# F28x7x_dcsm_z1_regs register map
Vendor: Texas Instruments
Peripheral module from a debugger description file (folder C2000).
Address unit: 16 bits
Registers are 32-bit, read-only, no defined reset value unless marked. A register's access mark holds for its fields unless they carry their own. Offsets are as the file gives them; lines under a group give offsets from that group; [hi:lo] are bit positions; {n}, {i} and the like mark numbered series; 'fields as' and 'values as' point back to an identical list; <NAME> marks a mode.

## DCSM_Z1_REGS — DCSM Z1 Registers
0x00 Z1_LINKPOINTER — Zone 1 Link Pointer
  [28:0] LINKPOINTER — Zone1 LINK Pointer.
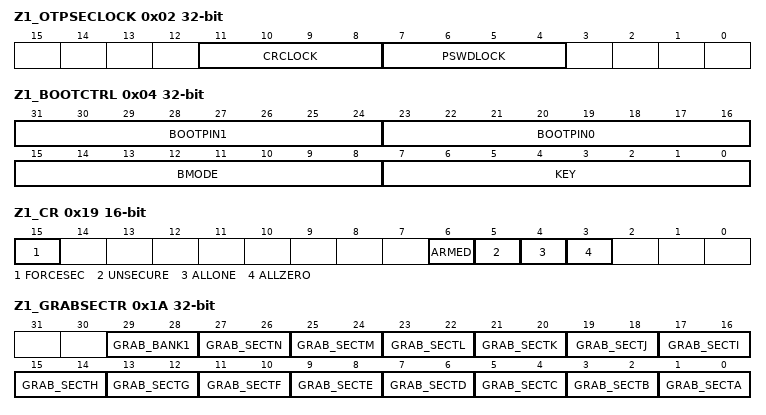
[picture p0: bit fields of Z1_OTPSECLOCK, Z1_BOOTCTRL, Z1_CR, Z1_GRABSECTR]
0x02 Z1_OTPSECLOCK — Zone 1 OTP Secure JTAG lock
  [11:8] CRCLOCK — Zone1 CRC Lock.
  [7:4] PSWDLOCK — Zone1 Password Lock.
0x04 Z1_BOOTCTRL — Boot Mode
  [31:24] BOOTPIN1 — OTP Boot Pin 1 Mapping
  [23:16] BOOTPIN0 — OTP Boot Pin 0 Mapping
  [15:8] BMODE — OTP Boot Mode
  [7:0] KEY — OTP Boot Key
0x06 Z1_LINKPOINTERERR — Link Pointer Error
  [31:0] Z1_LINKPOINTERERR — Formation of the resolved Link-Pointer error bits
{0x10+2i} Z1_CSMKEY{i} (i=0..3) — Zone 1 CSM Key {i}
0x19 Z1_CR 16-bit access not given — Zone 1 CSM Control Register
  [15] FORCESEC — Force Secure (access R=0/W)
  [6] ARMED ro — CSM Armed
  [5] UNSECURE ro — CSMPSWD Match CSMKEY
  [4] ALLONE ro — CSMPSWD All Ones
  [3] ALLZERO ro — CSMPSWD All Zeros
0x1A Z1_GRABSECTR — Zone 1 Grab Flash Sectors Register
  [29:28] GRAB_BANK1 — Grab BANK1 (all sectors of bank 1)
  [27:26] GRAB_SECTN — Grab Flash Sector N
  [25:24] GRAB_SECTM — Grab Flash Sector M
  [23:22] GRAB_SECTL — Grab Flash Sector L
  [21:20] GRAB_SECTK — Grab Flash Sector K
  [19:18] GRAB_SECTJ — Grab Flash Sector J
  [17:16] GRAB_SECTI — Grab Flash Sector I
  [15:14] GRAB_SECTH — Grab Flash Sector H
  [13:12] GRAB_SECTG — Grab Flash Sector G
  [11:10] GRAB_SECTF — Grab Flash Sector F
  [9:8] GRAB_SECTE — Grab Flash Sector E
  [7:6] GRAB_SECTD — Grab Flash Sector D
  [5:4] GRAB_SECTC — Grab Flash Sector C
  [3:2] GRAB_SECTB — Grab Flash Sector B
  [1:0] GRAB_SECTA — Grab Flash Sector A
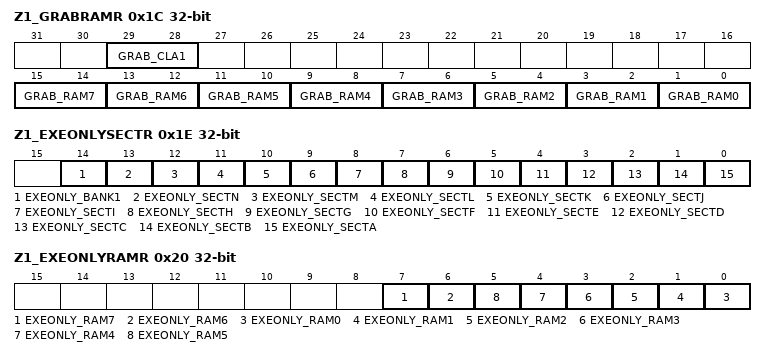
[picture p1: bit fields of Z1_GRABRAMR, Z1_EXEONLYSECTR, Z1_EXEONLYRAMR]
0x1C Z1_GRABRAMR — Zone 1 Grab RAM Blocks Register
  [29:28] GRAB_CLA1
  [15:14] GRAB_RAM7 — Grab RAM D1
  [13:12] GRAB_RAM6 — Grab RAM D0
  [2n+1:2n] GRAB_RAM{n} (n=0..5) — Grab RAM LS{n}
0x1E Z1_EXEONLYSECTR — Zone 1 Flash Execute_Only Sector Register
  [14] EXEONLY_BANK1 — Execute-Only Flash BANK1
  [13] EXEONLY_SECTN — Execute-Only Flash Sector N
  [12] EXEONLY_SECTM — Execute-Only Flash Sector M
  [11] EXEONLY_SECTL — Execute-Only Flash Sector L
  [10] EXEONLY_SECTK — Execute-Only Flash Sector K
  [9] EXEONLY_SECTJ — Execute-Only Flash Sector J
  [8] EXEONLY_SECTI — Execute-Only Flash Sector I
  [7] EXEONLY_SECTH — Execute-Only Flash Sector H
  [6] EXEONLY_SECTG — Execute-Only Flash Sector G
  [5] EXEONLY_SECTF — Execute-Only Flash Sector F
  [4] EXEONLY_SECTE — Execute-Only Flash Sector E
  [3] EXEONLY_SECTD — Execute-Only Flash Sector D
  [2] EXEONLY_SECTC — Execute-Only Flash Sector C
  [1] EXEONLY_SECTB — Execute-Only Flash Sector B
  [0] EXEONLY_SECTA — Execute-Only Flash Sector A
0x20 Z1_EXEONLYRAMR — Zone 1 RAM Execute_Only Block Register
  [7] EXEONLY_RAM7 — Execute-Only RAM D1
  [6] EXEONLY_RAM6 — Execute-Only RAM D0
  [n] EXEONLY_RAM{n} (n=0..5) — Execute-Only RAM LS{n}
